# STM32H743 register map
File version: 2.4
CPU: CM7 r0p1, little endian, MPU, FPU, 4 interrupt priority bits
Registers are 32-bit, read-write, reset 0x0 unless marked. A register's access mark holds for its fields unless they carry their own. Offsets are from the block's base; [hi:lo] are bit positions; {n}, {i} and the like mark numbered series.

## HRTIM_Common — 高分辨率定时器：通用功能
Base 0x40017780
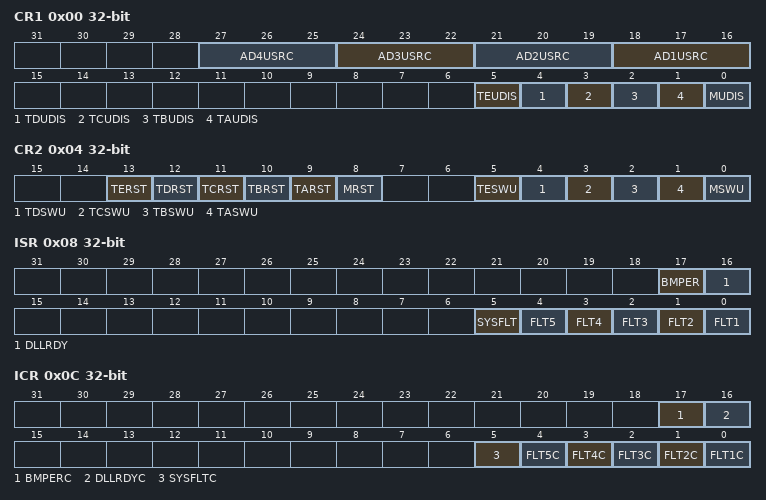
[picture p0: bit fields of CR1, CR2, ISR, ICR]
0x00 CR1 — 控制寄存器 1
  [3n+15:3n+13] AD{n}USRC (n=1..4) — ADC 触发 {n} 更新源
  [5] TEUDIS — 定时器 E 更新禁止
  [4] TDUDIS — 定时器 D 更新禁止
  [3] TCUDIS — 定时器 C 更新禁止
  [2] TBUDIS — 定时器 B 更新禁止
  [1] TAUDIS — 定时器 A 更新禁止
  [0] MUDIS — 主定时器更新禁止
0x04 CR2 — 控制寄存器 2
  [13] TERST — 定时器 E 计数器软件复位
  [12] TDRST — 定时器 D 计数器软件复位
  [11] TCRST — 定时器 C 计数器软件复位
  [10] TBRST — 定时器 B 计数器软件复位
  [9] TARST — 定时器 A 计数器软件复位
  [8] MRST — 主计数器软件复位
  [5] TESWU — 定时器 E 软件更新
  [4] TDSWU — 定时器 D 软件更新
  [3] TCSWU — 定时器 C 软件更新
  [2] TBSWU — 定时器 B 软件更新
  [1] TASWU — 定时器 A 软件更新
  [0] MSWU — 主定时器软件更新
0x08 ISR access per field — 中断状态寄存器
  [17] BMPER ro — 突发模式周期中断标志
  [16] DLLRDY ro — DLL 就绪中断标志
  [5] SYSFLT rw — 系统故障中断标志
  [n-1] FLT{n} ro (n=1..5) — 故障 {n} 中断标志
0x0C ICR access per field — 中断清除寄存器
  [17] BMPERC wo — 突发模式周期标志清除
  [16] DLLRDYC wo — DLL 就绪中断标志清除
  [5] SYSFLTC rw — 系统故障中断标志清除
  [n-1] FLT{n}C wo (n=1..5) — 故障 {n} 中断标志清除
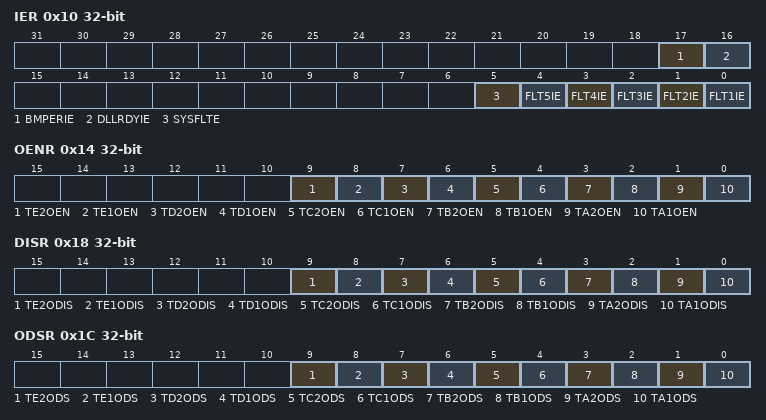
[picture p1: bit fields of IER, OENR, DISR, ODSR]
0x10 IER — 中断使能寄存器
  [17] BMPERIE — 突发模式周期中断使能
  [16] DLLRDYIE — DLL 就绪中断使能
  [5] SYSFLTE — 系统故障中断使能
  [n-1] FLT{n}IE (n=1..5) — 故障 {n} 中断使能
0x14 OENR wo — 输出使能寄存器
  [9] TE2OEN — 定时器 E 输出 2 使能
  [8] TE1OEN — 定时器 E 输出 1 使能
  [7] TD2OEN — 定时器 D 输出 2 使能
  [6] TD1OEN — 定时器 D 输出 1 使能
  [5] TC2OEN — 定时器 C 输出 2 使能
  [4] TC1OEN — 定时器 C 输出 1 使能
  [3] TB2OEN — 定时器 B 输出 2 使能
  [2] TB1OEN — 定时器 B 输出 1 使能
  [1] TA2OEN — 定时器 A 输出 2 使能
  [0] TA1OEN — 定时器 A 输出 1 使能
0x18 DISR — 输出禁止状态寄存器
  [9] TE2ODIS, [8] TE1ODIS, [7] TD2ODIS, [6] TD1ODIS, [5] TC2ODIS, [4] TC1ODIS, [3] TB2ODIS, [2] TB1ODIS, [1] TA2ODIS, [0] TA1ODIS
0x1C ODSR ro — 输出禁止状态寄存器
  [9] TE2ODS — 定时器 E 输出 2 禁止状态
  [8] TE1ODS — 定时器 E 输出 1 禁止状态
  [7] TD2ODS — 定时器 D 输出 2 禁止状态
  [6] TD1ODS — 定时器 D 输出 1 禁止状态
  [5] TC2ODS — 定时器 C 输出 2 禁止状态
  [4] TC1ODS — 定时器 C 输出 1 禁止状态
  [3] TB2ODS — 定时器 B 输出 2 禁止状态
  [2] TB1ODS — 定时器 B 输出 1 禁止状态
  [1] TA2ODS — 定时器 A 输出 2 禁止状态
  [0] TA1ODS — 定时器 A 输出 1 禁止状态
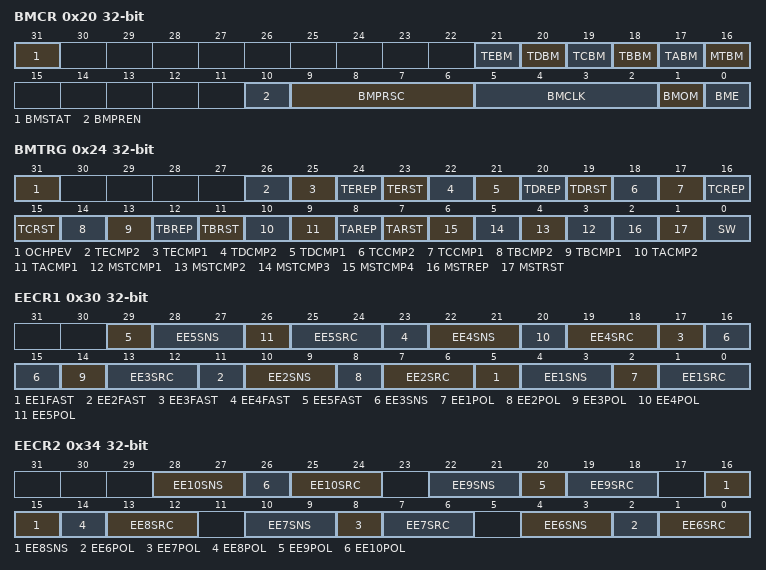
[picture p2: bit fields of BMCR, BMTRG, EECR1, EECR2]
0x20 BMCR — 突发模式控制寄存器
  [31] BMSTAT — 突发模式状态
  [21] TEBM — 定时器 E 突发模式
  [20] TDBM — 定时器 D 突发模式
  [19] TCBM — 定时器 C 突发模式
  [18] TBBM — 定时器 B 突发模式
  [17] TABM — 定时器 A 突发模式
  [16] MTBM — 主定时器突发模式
  [10] BMPREN — 突发模式预装载使能
  [9:6] BMPRSC — 突发模式预分频器
  [5:2] BMCLK — 突发模式时钟源
  [1] BMOM — 突发模式工作模式
  [0] BME — 突发模式使能
0x24 BMTRG — 突发模式触发寄存器
  [31] OCHPEV, [26] TECMP2, [25] TECMP1, [24] TEREP, [23] TERST, [22] TDCMP2, [21] TDCMP1, [20] TDREP, [19] TDRST, [18] TCCMP2, [17] TCCMP1, [16] TCREP, [15] TCRST, [14] TBCMP2, [13] TBCMP1, [12] TBREP, [11] TBRST, [10] TACMP2, [9] TACMP1, [8] TAREP, [7] TARST, [n+2] MSTCMP{n} (n=1..4), [2] MSTREP, [1] MSTRST, [0] SW
0x28 BMCMPR6 — 突发模式比较寄存器 6
  [15:0] BMCMP
0x2C BMPER — 突发模式周期寄存器
  [15:0] BMPER — 突发模式周期
0x30 EECR1 — 定时器外部事件控制寄存器 1
  [6n-1] EE{n}FAST (n=1..5) — 外部事件 {n} 快速模式
  [6n-2:6n-3] EE{n}SNS (n=1..5) — 外部事件 {n} 灵敏度
  [6n-4] EE{n}POL (n=1..5) — 外部事件 {n} 极性
  [6n-5:6n-6] EE{n}SRC (n=1..5) — 外部事件 {n} 源
0x34 EECR2 — 定时器外部事件控制寄存器 2
  [6n-32:6n-33] EE{n}SNS (n=6..10) — 外部事件 {n} 灵敏度
  [6n-34] EE{n}POL (n=6..10) — 外部事件 {n} 极性
  [6n-35:6n-36] EE{n}SRC (n=6..10) — 外部事件 {n} 源
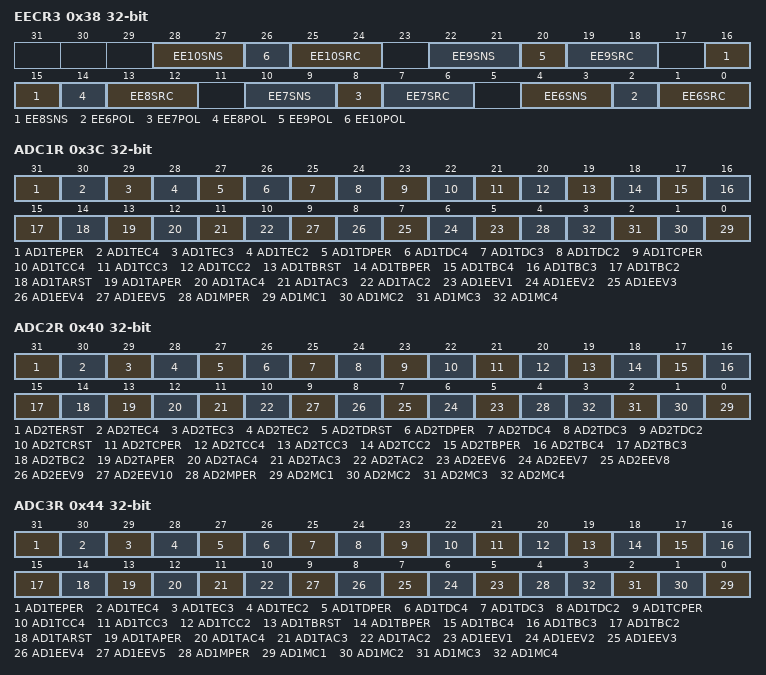
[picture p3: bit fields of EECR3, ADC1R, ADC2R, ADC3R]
0x38 EECR3 — 定时器外部事件控制寄存器 3
  [6n-32:6n-33] EE{n}SNS (n=6..10), [6n-34] EE{n}POL (n=6..10), [6n-35:6n-36] EE{n}SRC (n=6..10)
0x3C ADC1R — ADC 触发 1 寄存器
  [31] AD1TEPER — 定时器 E 周期上的 ADC 触发 1
  [30] AD1TEC4 — 定时器 E 比较 4 上的 ADC 触发 1
  [29] AD1TEC3 — 定时器 E 比较 3 上的 ADC 触发 1
  [28] AD1TEC2 — 定时器 E 比较 2 上的 ADC 触发 1
  [27] AD1TDPER — 定时器 D 周期上的 ADC 触发 1
  [26] AD1TDC4 — 定时器 D 比较 4 上的 ADC 触发 1
  [25] AD1TDC3 — 定时器 D 比较 3 上的 ADC 触发 1
  [24] AD1TDC2 — 定时器 D 比较 2 上的 ADC 触发 1
  [23] AD1TCPER — 定时器 C 周期上的 ADC 触发 1
  [22] AD1TCC4 — 定时器 C 比较 4 上的 ADC 触发 1
  [21] AD1TCC3 — 定时器 C 比较 3 上的 ADC 触发 1
  [20] AD1TCC2 — 定时器 C 比较 2 上的 ADC 触发 1
  [19] AD1TBRST — 定时器 B 复位上的 ADC 触发 1
  [18] AD1TBPER — 定时器 B 周期上的 ADC 触发 1
  [17] AD1TBC4 — 定时器 B 比较 4 上的 ADC 触发 1
  [16] AD1TBC3 — 定时器 B 比较 3 上的 ADC 触发 1
  [15] AD1TBC2 — 定时器 B 比较 2 上的 ADC 触发 1
  [14] AD1TARST — 定时器 A 复位上的 ADC 触发 1
  [13] AD1TAPER — 定时器 A 周期上的 ADC 触发 1
  [12] AD1TAC4 — 定时器 A 比较 4 上的 ADC 触发 1
  [11] AD1TAC3 — 定时器 A 比较 3 上的 ADC 触发 1
  [10] AD1TAC2 — 定时器 A 比较 2 上的 ADC 触发 1
  [n+4] AD1EEV{n} (n=1..5) — 外部事件 {n} 上的 ADC 触发 1
  [4] AD1MPER — 主定时器周期上的 ADC 触发 1
  [n-1] AD1MC{n} (n=1..4) — 主定时器比较 {n} 上的 ADC 触发 1
0x40 ADC2R — ADC 触发 2 寄存器
  [31] AD2TERST — 定时器 E 复位上的 ADC 触发 2
  [30] AD2TEC4 — 定时器 E 比较 4 上的 ADC 触发 2
  [29] AD2TEC3 — 定时器 E 比较 3 上的 ADC 触发 2
  [28] AD2TEC2 — 定时器 E 比较 2 上的 ADC 触发 2
  [27] AD2TDRST — 定时器 D 复位上的 ADC 触发 2
  [26] AD2TDPER — 定时器 D 周期上的 ADC 触发 2
  [25] AD2TDC4 — 定时器 D 比较 4 上的 ADC 触发 2
  [24] AD2TDC3 — 定时器 D 比较 3 上的 ADC 触发 2
  [23] AD2TDC2 — 定时器 D 比较 2 上的 ADC 触发 2
  [22] AD2TCRST — 定时器 C 复位上的 ADC 触发 2
  [21] AD2TCPER — 定时器 C 周期上的 ADC 触发 2
  [20] AD2TCC4 — 定时器 C 比较 4 上的 ADC 触发 2
  [19] AD2TCC3 — 定时器 C 比较 3 上的 ADC 触发 2
  [18] AD2TCC2 — 定时器 C 比较 2 上的 ADC 触发 2
  [17] AD2TBPER — 定时器 B 周期上的 ADC 触发 2
  [16] AD2TBC4 — 定时器 B 比较 4 上的 ADC 触发 2
  [15] AD2TBC3 — 定时器 B 比较 3 上的 ADC 触发 2
  [14] AD2TBC2 — 定时器 B 比较 2 上的 ADC 触发 2
  [13] AD2TAPER — 定时器 A 周期上的 ADC 触发 2
  [12] AD2TAC4 — 定时器 A 比较 4 上的 ADC 触发 2
  [11] AD2TAC3 — 定时器 A 比较 3 上的 ADC 触发 2
  [10] AD2TAC2 — 定时器 A 比较 2 上的 ADC 触发 2
  [n-1] AD2EEV{n} (n=6..10) — 外部事件 {n} 上的 ADC 触发 2
  [4] AD2MPER — 主定时器周期上的 ADC 触发 2
  [n-1] AD2MC{n} (n=1..4) — 主定时器比较 {n} 上的 ADC 触发 2
0x44 ADC3R — ADC 触发 3 寄存器
  [31] AD1TEPER, [30] AD1TEC4, [29] AD1TEC3, [28] AD1TEC2, [27] AD1TDPER, [26] AD1TDC4, [25] AD1TDC3, [24] AD1TDC2, [23] AD1TCPER, [22] AD1TCC4, [21] AD1TCC3, [20] AD1TCC2, [19] AD1TBRST, [18] AD1TBPER, [17] AD1TBC4, [16] AD1TBC3, [15] AD1TBC2, [14] AD1TARST, [13] AD1TAPER, [12] AD1TAC4, [11] AD1TAC3, [10] AD1TAC2, [n+4] AD1EEV{n} (n=1..5), [4] AD1MPER, [n-1] AD1MC{n} (n=1..4)
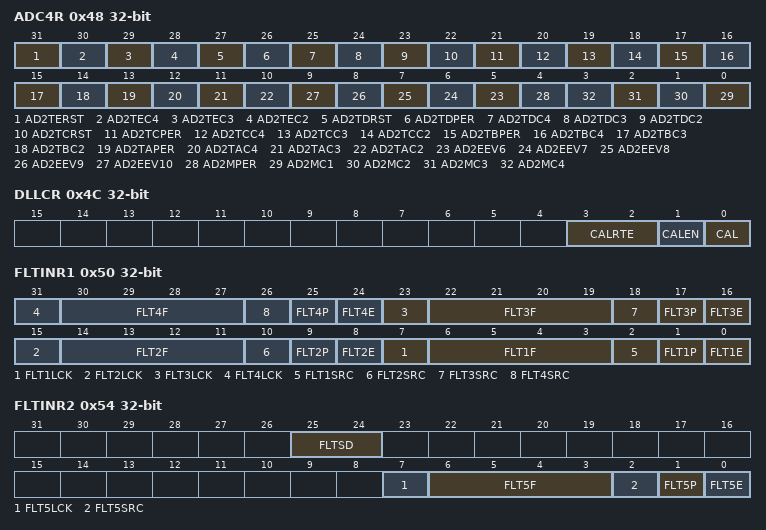
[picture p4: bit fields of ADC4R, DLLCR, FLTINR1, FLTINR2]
0x48 ADC4R — ADC 触发 4 寄存器
  [31] AD2TERST, [30] AD2TEC4, [29] AD2TEC3, [28] AD2TEC2, [27] AD2TDRST, [26] AD2TDPER, [25] AD2TDC4, [24] AD2TDC3, [23] AD2TDC2, [22] AD2TCRST, [21] AD2TCPER, [20] AD2TCC4, [19] AD2TCC3, [18] AD2TCC2, [17] AD2TBPER, [16] AD2TBC4, [15] AD2TBC3, [14] AD2TBC2, [13] AD2TAPER, [12] AD2TAC4, [11] AD2TAC3, [10] AD2TAC2, [n-1] AD2EEV{n} (n=6..10), [4] AD2MPER, [n-1] AD2MC{n} (n=1..4)
0x4C DLLCR — DLL 控制寄存器
  [3:2] CALRTE — DLL 校准速率
  [1] CALEN — DLL 校准使能
  [0] CAL — DLL 校准启动
0x50 FLTINR1 — HRTIM 故障输入寄存器 1
  [8n-1] FLT{n}LCK (n=1..4), [8n-2:8n-5] FLT{n}F (n=1..4), [8n-6] FLT{n}SRC (n=1..4), [8n-7] FLT{n}P (n=1..4), [8n-8] FLT{n}E (n=1..4)
0x54 FLTINR2 — HRTIM 故障输入寄存器 2
  [25:24] FLTSD, [7] FLT5LCK, [6:3] FLT5F, [2] FLT5SRC, [1] FLT5P, [0] FLT5E
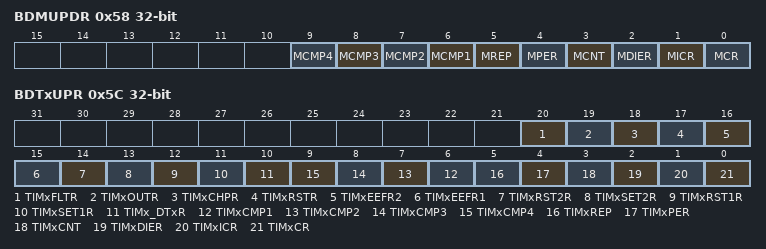
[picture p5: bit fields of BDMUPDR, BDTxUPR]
0x58 BDMUPDR — 突发 DMA 主定时器更新寄存器
  [n+5] MCMP{n} (n=1..4), [5] MREP, [4] MPER, [3] MCNT, [2] MDIER, [1] MICR, [0] MCR
0x5C BDTxUPR — 突发 DMA 定时器x 更新寄存器
  [20] TIMxFLTR — HRTIM_FLTxR 寄存器更新使能
  [19] TIMxOUTR — HRTIM_OUTxR 寄存器更新使能
  [18] TIMxCHPR — HRTIM_CHPxR 寄存器更新使能
  [17] TIMxRSTR — HRTIM_RSTxR 寄存器更新使能
  [16] TIMxEEFR2 — HRTIM_EEFxR2 寄存器更新使能
  [15] TIMxEEFR1 — HRTIM_EEFxR1 寄存器更新使能
  [14] TIMxRST2R — HRTIM_RST2xR 寄存器更新使能
  [13] TIMxSET2R — HRTIM_SET2xR 寄存器更新使能
  [12] TIMxRST1R — HRTIM_RST1xR 寄存器更新使能
  [11] TIMxSET1R — HRTIM_SET1xR 寄存器更新使能
  [10] TIMx_DTxR — HRTIM_DTxR 寄存器更新使能
  [n+5] TIMxCMP{n} (n=1..4) — HRTIM_CMP{n}xR 寄存器更新使能
  [5] TIMxREP — HRTIM_REPxR 寄存器更新使能
  [4] TIMxPER — HRTIM_PERxR 寄存器更新使能
  [3] TIMxCNT — HRTIM_CNTxR 寄存器更新使能
  [2] TIMxDIER — HRTIM_TIMxDIER 寄存器更新使能
  [1] TIMxICR — HRTIM_TIMxICR 寄存器更新使能
  [0] TIMxCR — HRTIM_TIMxCR 寄存器更新使能
0x60 BDMADR — 突发 DMA 数据寄存器
